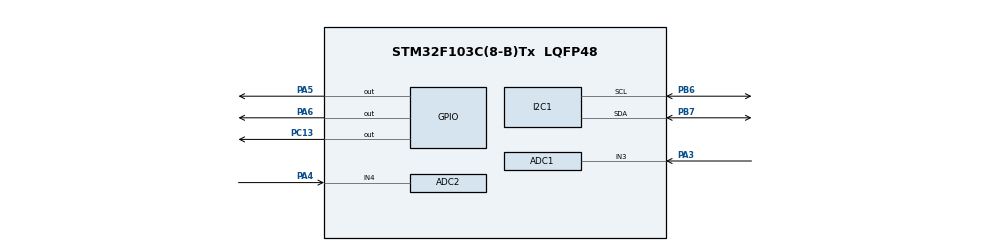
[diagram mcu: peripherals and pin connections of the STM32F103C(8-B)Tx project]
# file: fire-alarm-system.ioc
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ADC1.Channel-1\#ChannelRegularConversion=ADC_CHANNEL_3
ADC1.NbrOfConversionFlag=1
ADC1.Rank-1\#ChannelRegularConversion=1
ADC1.SamplingTime-1\#ChannelRegularConversion=ADC_SAMPLETIME_1CYCLE_5
ADC1.master=1
ADC2.Channel-0\#ChannelRegularConversion=ADC_CHANNEL_4
ADC2.NbrOfConversionFlag=1
ADC2.Rank-0\#ChannelRegularConversion=1
ADC2.SamplingTime-0\#ChannelRegularConversion=ADC_SAMPLETIME_1CYCLE_5
I2C1.I2C_Mode=I2C_Fast
Mcu.Family=STM32F1
Mcu.Name=STM32F103C(8-B)Tx
Mcu.Package=LQFP48
NVIC.PriorityGroup=NVIC_PRIORITYGROUP_4
PA13.Mode=Serial_Wire
PA13.Signal=SYS_JTMS-SWDIO
PA14.Mode=Serial_Wire
PA14.Signal=SYS_JTCK-SWCLK
PA3.Signal=ADCx_IN3
PA4.Signal=ADCx_IN4
PA5.Signal=GPIO_Output
PA6.Signal=GPIO_Output
PB6.Mode=I2C
PB6.Signal=I2C1_SCL
PB7.Mode=I2C
PB7.Signal=I2C1_SDA
PC13-TAMPER-RTC.Signal=GPIO_Output
ProjectManager.HeapSize=0x200
ProjectManager.StackSize=0x400
ProjectManager.TargetToolchain=STM32CubeIDE
RCC.APB1Freq_Value=8000000
RCC.APB2Freq_Value=8000000
SH.ADCx_IN3.0=ADC1_IN3,IN3
SH.ADCx_IN4.0=ADC2_IN4,IN4
board=custom

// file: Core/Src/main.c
/* USER CODE BEGIN Header */
/**
  ******************************************************************************
  * @file           : main.c
  * @brief          : Main program body
  ******************************************************************************
  * @attention
  *
  * Copyright (c) 2024 STMicroelectronics.
  * All rights reserved.
  *
  * This software is licensed under terms that can be found in the LICENSE file
  * in the root directory of this software component.
  * If no LICENSE file comes with this software, it is provided AS-IS.
  *
  ******************************************************************************
  */
/* USER CODE END Header */

#include "main.h"
#include "fonts.h"
#include "ssd1306.h"

ADC_HandleTypeDef hadc1;
ADC_HandleTypeDef hadc2;
I2C_HandleTypeDef hi2c1;

/* USER CODE BEGIN PV */
uint32_t ADC_VAL_ALARM = 0;
uint32_t ADC_VAL_GAS = 0;
/* USER CODE END PV */

void SystemClock_Config(void);
static void MX_GPIO_Init(void);
static void MX_ADC1_Init(void);
static void MX_ADC2_Init(void);
static void MX_I2C1_Init(void);

int main(void)
{

  /* MCU Configuration--------------------------------------------------------*/
  HAL_Init();
  SystemClock_Config();

  /* Initialize all configured peripherals */
  MX_GPIO_Init();
  MX_ADC1_Init();
  MX_ADC2_Init();
  MX_I2C1_Init();

  /* USER CODE BEGIN 2 */
  SSD1306_Init();
  char str1[5], str2[5];

  // Tien
  SSD1306_GotoXY(0, 0);
  SSD1306_Puts("WELCOME", &Font_11x18, 1);
  SSD1306_GotoXY(0, 30);
  SSD1306_Puts(" PTIT ", &Font_11x18, 1);
  SSD1306_UpdateScreen();
  HAL_Delay(1000);

  // Tien
  SSD1306_ScrollRight(0, 7);
  HAL_Delay(1000);
  SSD1306_ScrollLeft(0, 7);
  HAL_Delay(1000);
  SSD1306_Stopscroll();
  SSD1306_Clear();
  /* USER CODE END 2 */

  /* Infinite loop */
  /* USER CODE BEGIN WHILE */
  while (1)
  {
	  // Quy Phuoc
    HAL_ADC_Start(&hadc1);
    HAL_ADC_Start(&hadc2);
    HAL_Delay(20);
    // 2 bien dung de luu tin hieu (Quy Phuoc)
    ADC_VAL_ALARM = HAL_ADC_GetValue(&hadc1);
    ADC_VAL_GAS = HAL_ADC_GetValue(&hadc2);
    // Stop bien doi ADC (Quy Phuoc)
    HAL_ADC_Stop(&hadc1);
    HAL_ADC_Stop(&hadc2);

    if (ADC_VAL_ALARM > 3000 || ADC_VAL_GAS > 3000)
    {
    // Coi reo va den sang (Ly Hieu)
      HAL_GPIO_WritePin(GPIOA, GPIO_PIN_5, GPIO_PIN_RESET);
      HAL_GPIO_WritePin(GPIOC, GPIO_PIN_13, GPIO_PIN_RESET);
      HAL_GPIO_WritePin(GPIOA, GPIO_PIN_7, GPIO_PIN_RESET);
    } else {
    // Coi va den tat (Ly Hieu)
      HAL_GPIO_WritePin(GPIOA, GPIO_PIN_5, GPIO_PIN_SET);
      HAL_GPIO_WritePin(GPIOC, GPIO_PIN_13, GPIO_PIN_SET);
      HAL_GPIO_WritePin(GPIOA, GPIO_PIN_7, GPIO_PIN_SET);
    }

    snprintf(str1, sizeof(str1), "%lu", ADC_VAL_ALARM);
    snprintf(str2, sizeof(str2), "%lu", ADC_VAL_GAS);

    // Tien
    SSD1306_GotoXY(0, 0);
    SSD1306_Puts("HY026: ", &Font_11x18, 1);
    SSD1306_Puts(str1, &Font_11x18, 1);
    SSD1306_GotoXY(0, 30);
    SSD1306_Puts("GAS: ", &Font_11x18, 1);
    SSD1306_Puts(str2, &Font_11x18, 1);
    SSD1306_UpdateScreen();

  }
}

void SystemClock_Config(void)
{
  RCC_OscInitTypeDef RCC_OscInitStruct = {0};
  RCC_ClkInitTypeDef RCC_ClkInitStruct = {0};
  RCC_PeriphCLKInitTypeDef PeriphClkInit = {0};

  RCC_OscInitStruct.OscillatorType = RCC_OSCILLATORTYPE_HSI;
  RCC_OscInitStruct.HSIState = RCC_HSI_ON;
  RCC_OscInitStruct.HSICalibrationValue = RCC_HSICALIBRATION_DEFAULT;
  RCC_OscInitStruct.PLL.PLLState = RCC_PLL_NONE;
  if (HAL_RCC_OscConfig(&RCC_OscInitStruct) != HAL_OK)
  {
    Error_Handler();
  }

  RCC_ClkInitStruct.ClockType = RCC_CLOCKTYPE_HCLK | RCC_CLOCKTYPE_SYSCLK | RCC_CLOCKTYPE_PCLK1 | RCC_CLOCKTYPE_PCLK2;
  RCC_ClkInitStruct.SYSCLKSource = RCC_SYSCLKSOURCE_HSI;
  RCC_ClkInitStruct.AHBCLKDivider = RCC_SYSCLK_DIV1;
  RCC_ClkInitStruct.APB1CLKDivider = RCC_HCLK_DIV1;
  RCC_ClkInitStruct.APB2CLKDivider = RCC_HCLK_DIV1;

  if (HAL_RCC_ClockConfig(&RCC_ClkInitStruct, FLASH_LATENCY_0) != HAL_OK)
  {
    Error_Handler();
  }

  PeriphClkInit.PeriphClockSelection = RCC_PERIPHCLK_ADC;
  PeriphClkInit.AdcClockSelection = RCC_ADCPCLK2_DIV2;
  if (HAL_RCCEx_PeriphCLKConfig(&PeriphClkInit) != HAL_OK)
  {
    Error_Handler();
  }
}

static void MX_ADC1_Init(void)
{
  ADC_ChannelConfTypeDef sConfig = {0};

  hadc1.Instance = ADC1;
  hadc1.Init.ScanConvMode = ADC_SCAN_DISABLE;
  hadc1.Init.ContinuousConvMode = DISABLE;
  hadc1.Init.DiscontinuousConvMode = DISABLE;
  hadc1.Init.ExternalTrigConv = ADC_SOFTWARE_START;
  hadc1.Init.DataAlign = ADC_DATAALIGN_RIGHT;
  hadc1.Init.NbrOfConversion = 1;
  if (HAL_ADC_Init(&hadc1) != HAL_OK)
  {
    Error_Handler();
  }

  sConfig.Channel = ADC_CHANNEL_3;
  sConfig.Rank = ADC_REGULAR_RANK_1;
  sConfig.SamplingTime = ADC_SAMPLETIME_1CYCLE_5;
  if (HAL_ADC_ConfigChannel(&hadc1, &sConfig) != HAL_OK)
  {
    Error_Handler();
  }
}

static void MX_ADC2_Init(void)
{
  ADC_ChannelConfTypeDef sConfig = {0};

  hadc2.Instance = ADC2;
  hadc2.Init.ScanConvMode = ADC_SCAN_DISABLE;
  hadc2.Init.ContinuousConvMode = DISABLE;
  hadc2.Init.DiscontinuousConvMode = DISABLE;
  hadc2.Init.ExternalTrigConv = ADC_SOFTWARE_START;
  hadc2.Init.DataAlign = ADC_DATAALIGN_RIGHT;
  hadc2.Init.NbrOfConversion = 1;
  if (HAL_ADC_Init(&hadc2) != HAL_OK)
  {
    Error_Handler();
  }

  sConfig.Channel = ADC_CHANNEL_4;
  sConfig.Rank = ADC_REGULAR_RANK_1;
  sConfig.SamplingTime = ADC_SAMPLETIME_1CYCLE_5;
  if (HAL_ADC_ConfigChannel(&hadc2, &sConfig) != HAL_OK)
  {
    Error_Handler();
  }
}

static void MX_I2C1_Init(void)
{
  hi2c1.Instance = I2C1;
  hi2c1.Init.ClockSpeed = 400000;
  hi2c1.Init.DutyCycle = I2C_DUTYCYCLE_2;
  hi2c1.Init.OwnAddress1 = 0;
  hi2c1.Init.AddressingMode = I2C_ADDRESSINGMODE_7BIT;
  hi2c1.Init.DualAddressMode = I2C_DUALADDRESS_DISABLE;
  hi2c1.Init.OwnAddress2 = 0;
  hi2c1.Init.GeneralCallMode = I2C_GENERALCALL_DISABLE;
  hi2c1.Init.NoStretchMode = I2C_NOSTRETCH_DISABLE;
  if (HAL_I2C_Init(&hi2c1) != HAL_OK)
  {
    Error_Handler();
  }
}

static void MX_GPIO_Init(void)
{
  GPIO_InitTypeDef GPIO_InitStruct = {0};

  __HAL_RCC_GPIOC_CLK_ENABLE();
  __HAL_RCC_GPIOA_CLK_ENABLE();
  __HAL_RCC_GPIOB_CLK_ENABLE();

  HAL_GPIO_WritePin(GPIOC, GPIO_PIN_13, GPIO_PIN_RESET);
  HAL_GPIO_WritePin(GPIOA, GPIO_PIN_5 | GPIO_PIN_7, GPIO_PIN_RESET);

  // LED Port C - Pin 13
  GPIO_InitStruct.Pin = GPIO_PIN_13;
  GPIO_InitStruct.Mode = GPIO_MODE_OUTPUT_PP;
  GPIO_InitStruct.Pull = GPIO_NOPULL;
  GPIO_InitStruct.Speed = GPIO_SPEED_FREQ_LOW;
  HAL_GPIO_Init(GPIOC, &GPIO_InitStruct);

  // Coi Port A - Pin 5
  GPIO_InitStruct.Pin = GPIO_PIN_5 | GPIO_PIN_7;
  GPIO_InitStruct.Mode = GPIO_MODE_OUTPUT_PP;
  GPIO_InitStruct.Pull = GPIO_NOPULL;
  GPIO_InitStruct.Speed = GPIO_SPEED_FREQ_LOW;
  HAL_GPIO_Init(GPIOA, &GPIO_InitStruct);
}

void Error_Handler(void)
{
  __disable_irq();
  while (1)
  {
  }
}
